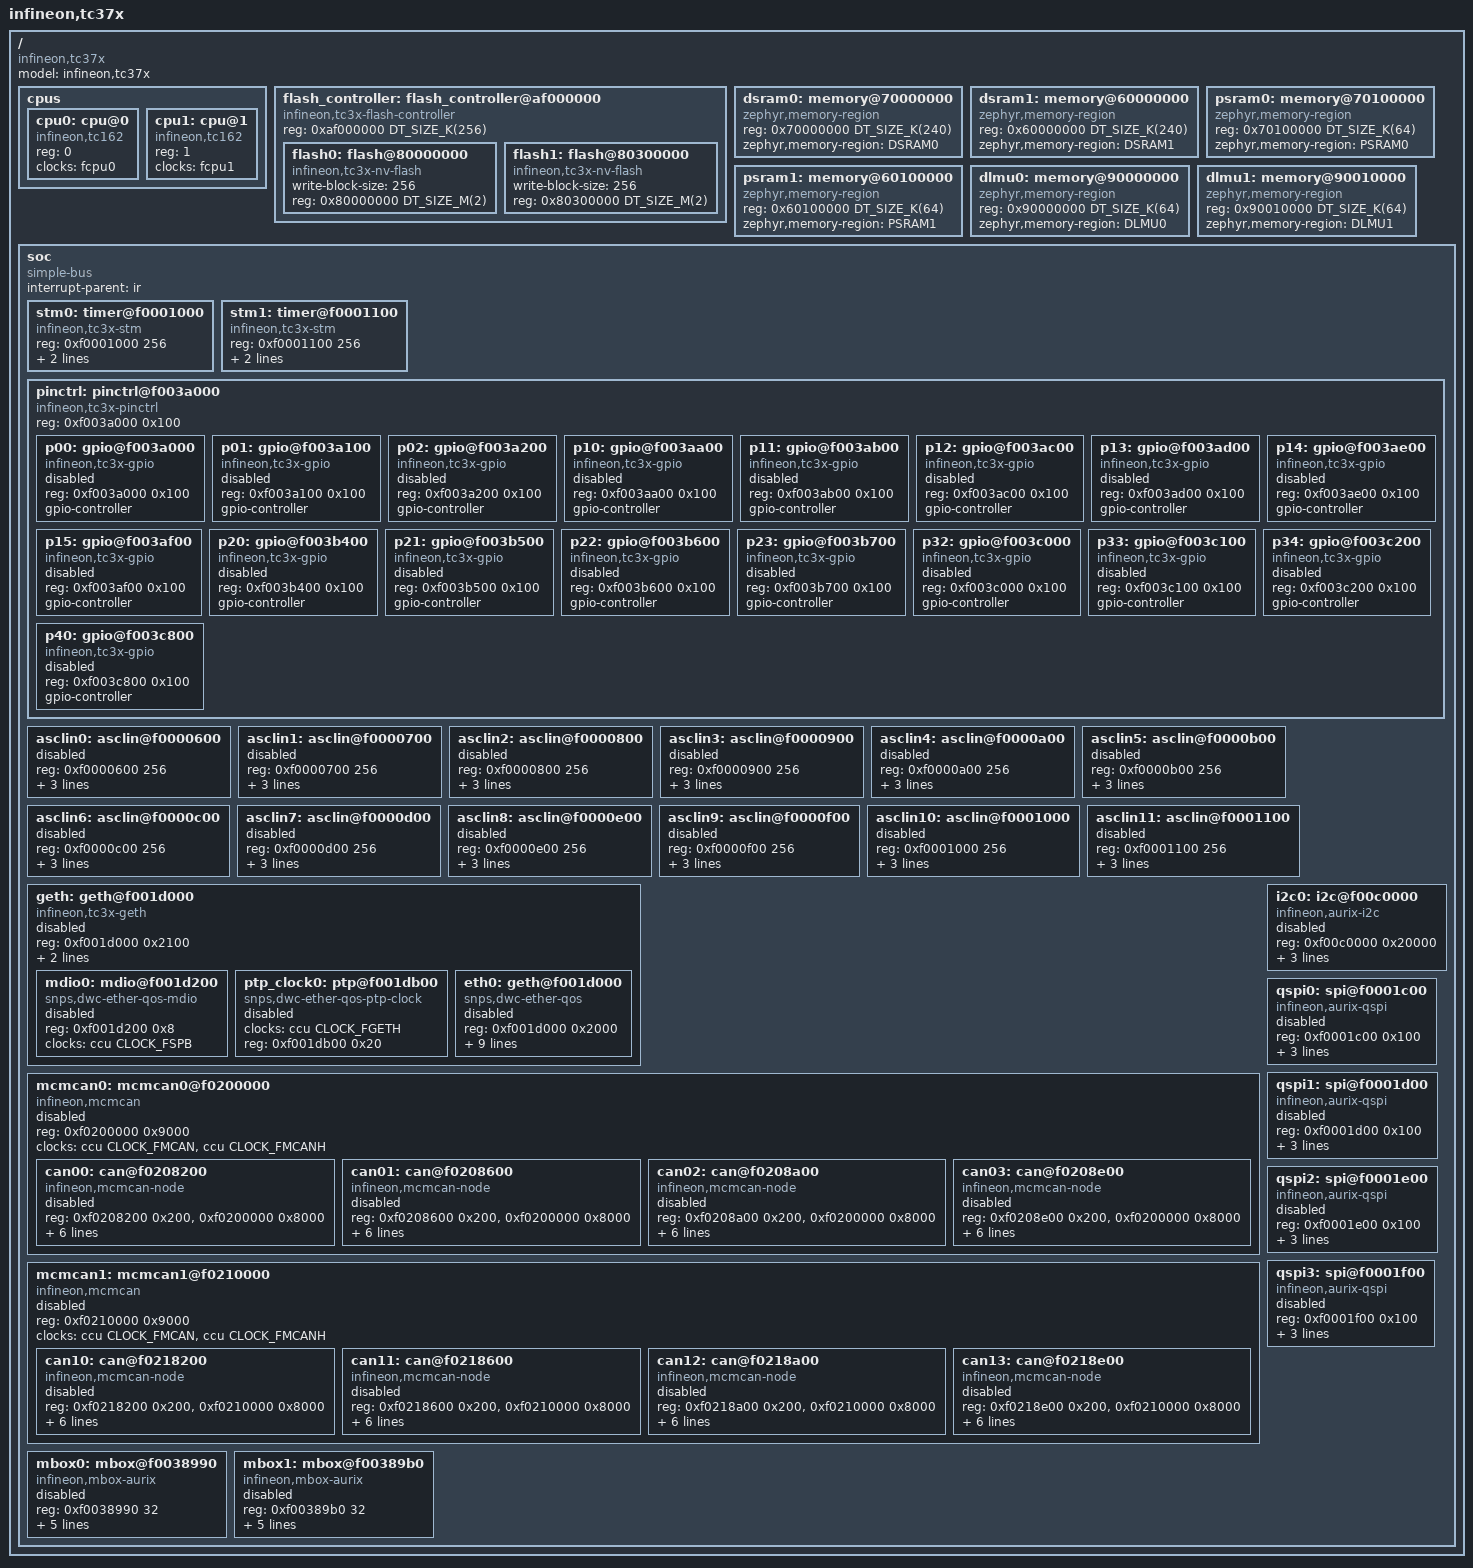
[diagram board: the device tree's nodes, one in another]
/*
 * Copyright (c) 2026 Infineon Technologies AG
 *
 * SPDX-License-Identifier: Apache-2.0
 */

#include <mem.h>
#include <freq.h>
#include <skeleton.dtsi>
#include <zephyr/dt-bindings/clock/tc3x_clock.h>
#include <zephyr/dt-bindings/gpio/gpio.h>
#include <infineon/tc3x/tc36x-irq.h>
#include <infineon/tc3x/tc3x-common.dtsi>

/ {
	model = "infineon,tc37x";
	compatible = "infineon,tc37x";

	cpus {
		#address-cells = <1>;
		#size-cells = <0>;

		cpu0: cpu@0 {
			compatible = "infineon,tc162";
			reg = <0>;
			clocks = <&fcpu0>;
		};

		cpu1: cpu@1 {
			compatible = "infineon,tc162";
			reg = <1>;
			clocks = <&fcpu1>;
		};
	};

	flash_controller: flash_controller@af000000 {
		compatible = "infineon,tc3x-flash-controller";
		#address-cells = <1>;
		#size-cells = <1>;
		reg = <0xaf000000 DT_SIZE_K(256)>;

		flash0: flash@80000000 {
			compatible = "infineon,tc3x-nv-flash", "soc-nv-flash";
			write-block-size = <256>;
			reg = <0x80000000 DT_SIZE_M(2)>;
		};

		flash1: flash@80300000 {
			compatible = "infineon,tc3x-nv-flash", "soc-nv-flash";
			write-block-size = <256>;
			reg = <0x80300000 DT_SIZE_M(2)>;
		};
	};

	dsram0: memory@70000000 {
		compatible = "zephyr,memory-region", "mmio-sram";
		reg = <0x70000000 DT_SIZE_K(240)>;
		zephyr,memory-region = "DSRAM0";
	};

	dsram1: memory@60000000 {
		compatible = "zephyr,memory-region", "mmio-sram";
		reg = <0x60000000 DT_SIZE_K(240)>;
		zephyr,memory-region = "DSRAM1";
	};

	psram0: memory@70100000 {
		compatible = "zephyr,memory-region", "mmio-sram";
		reg = <0x70100000 DT_SIZE_K(64)>;
		zephyr,memory-region = "PSRAM0";
	};

	psram1: memory@60100000 {
		compatible = "zephyr,memory-region", "mmio-sram";
		reg = <0x60100000 DT_SIZE_K(64)>;
		zephyr,memory-region = "PSRAM1";
	};

	dlmu0: memory@90000000 {
		compatible = "zephyr,memory-region", "mmio-sram";
		reg = <0x90000000 DT_SIZE_K(64)>;
		zephyr,memory-region = "DLMU0";
	};

	dlmu1: memory@90010000 {
		compatible = "zephyr,memory-region", "mmio-sram";
		reg = <0x90010000 DT_SIZE_K(64)>;
		zephyr,memory-region = "DLMU1";
	};

	soc {
		#address-cells = <1>;
		#size-cells = <1>;
		interrupt-parent = <&ir>;
		compatible = "simple-bus";
		ranges;

		stm0: timer@f0001000 {
			compatible = "infineon,tc3x-stm";
			reg = <0xf0001000 256>;
			clocks = <&fstm>;
			interrupts = <IRQ_STM0_SR0 1>;
		};

		stm1: timer@f0001100 {
			compatible = "infineon,tc3x-stm";
			reg = <0xf0001100 256>;
			clocks = <&fstm>;
			interrupts = <IRQ_STM1_SR0 1>;
		};

		pinctrl: pinctrl@f003a000 {
			compatible = "infineon,tc3x-pinctrl";
			reg = <0xf003a000 0x100>;
			#address-cells = <1>;
			#size-cells = <1>;

			p00: gpio@f003a000 {
				compatible = "infineon,tc3x-gpio";
				reg = <0xf003a000 0x100>;
				gpio-controller;
				#gpio-cells = <2>;
				status = "disabled";
			};

			p01: gpio@f003a100 {
				compatible = "infineon,tc3x-gpio";
				reg = <0xf003a100 0x100>;
				gpio-controller;
				#gpio-cells = <2>;
				status = "disabled";
			};

			p02: gpio@f003a200 {
				compatible = "infineon,tc3x-gpio";
				reg = <0xf003a200 0x100>;
				gpio-controller;
				#gpio-cells = <2>;
				status = "disabled";
			};

			p10: gpio@f003aa00 {
				compatible = "infineon,tc3x-gpio";
				reg = <0xf003aa00 0x100>;
				gpio-controller;
				#gpio-cells = <2>;
				status = "disabled";
			};

			p11: gpio@f003ab00 {
				compatible = "infineon,tc3x-gpio";
				reg = <0xf003ab00 0x100>;
				gpio-controller;
				#gpio-cells = <2>;
				status = "disabled";
			};

			p12: gpio@f003ac00 {
				compatible = "infineon,tc3x-gpio";
				reg = <0xf003ac00 0x100>;
				gpio-controller;
				#gpio-cells = <2>;
				status = "disabled";
			};

			p13: gpio@f003ad00 {
				compatible = "infineon,tc3x-gpio";
				reg = <0xf003ad00 0x100>;
				gpio-controller;
				#gpio-cells = <2>;
				status = "disabled";
			};

			p14: gpio@f003ae00 {
				compatible = "infineon,tc3x-gpio";
				reg = <0xf003ae00 0x100>;
				gpio-controller;
				#gpio-cells = <2>;
				status = "disabled";
			};

			p15: gpio@f003af00 {
				compatible = "infineon,tc3x-gpio";
				reg = <0xf003af00 0x100>;
				gpio-controller;
				#gpio-cells = <2>;
				status = "disabled";
			};

			p20: gpio@f003b400 {
				compatible = "infineon,tc3x-gpio";
				reg = <0xf003b400 0x100>;
				gpio-controller;
				#gpio-cells = <2>;
				status = "disabled";
			};

			p21: gpio@f003b500 {
				compatible = "infineon,tc3x-gpio";
				reg = <0xf003b500 0x100>;
				gpio-controller;
				#gpio-cells = <2>;
				status = "disabled";
			};

			p22: gpio@f003b600 {
				compatible = "infineon,tc3x-gpio";
				reg = <0xf003b600 0x100>;
				gpio-controller;
				#gpio-cells = <2>;
				status = "disabled";
			};

			p23: gpio@f003b700 {
				compatible = "infineon,tc3x-gpio";
				reg = <0xf003b700 0x100>;
				gpio-controller;
				#gpio-cells = <2>;
				status = "disabled";
			};

			p32: gpio@f003c000 {
				compatible = "infineon,tc3x-gpio";
				reg = <0xf003c000 0x100>;
				gpio-controller;
				#gpio-cells = <2>;
				status = "disabled";
			};

			p33: gpio@f003c100 {
				compatible = "infineon,tc3x-gpio";
				reg = <0xf003c100 0x100>;
				gpio-controller;
				#gpio-cells = <2>;
				status = "disabled";
			};

			p34: gpio@f003c200 {
				compatible = "infineon,tc3x-gpio";
				reg = <0xf003c200 0x100>;
				gpio-controller;
				#gpio-cells = <2>;
				status = "disabled";
			};

			p40: gpio@f003c800 {
				compatible = "infineon,tc3x-gpio";
				reg = <0xf003c800 0x100>;
				gpio-controller;
				#gpio-cells = <2>;
				status = "disabled";
			};
		};

		asclin0: asclin@f0000600 {
			reg = <0xf0000600 256>;
			interrupts = <IRQ_ASCLIN0_TX 2>,
				     <IRQ_ASCLIN0_RX 3>,
				     <IRQ_ASCLIN0_ERR 4>;
			interrupt-names = "tx", "rx", "err";
			clocks = <&ccu CLOCK_FASCLINF>, <&ccu CLOCK_FASCLINS>;
			clock-names = "fasclinf", "fasclins";
			status = "disabled";
		};

		asclin1: asclin@f0000700 {
			reg = <0xf0000700 256>;
			interrupts = <IRQ_ASCLIN1_TX 2>,
				     <IRQ_ASCLIN1_RX 3>,
				     <IRQ_ASCLIN1_ERR 4>;
			interrupt-names = "tx", "rx", "err";
			clocks = <&ccu CLOCK_FASCLINF>, <&ccu CLOCK_FASCLINS>;
			clock-names = "fasclinf", "fasclins";
			status = "disabled";
		};

		asclin2: asclin@f0000800 {
			reg = <0xf0000800 256>;
			interrupts = <IRQ_ASCLIN2_TX 2>,
				     <IRQ_ASCLIN2_RX 3>,
				     <IRQ_ASCLIN2_ERR 4>;
			interrupt-names = "tx", "rx", "err";
			clocks = <&ccu CLOCK_FASCLINF>, <&ccu CLOCK_FASCLINS>;
			clock-names = "fasclinf", "fasclins";
			status = "disabled";
		};

		asclin3: asclin@f0000900 {
			reg = <0xf0000900 256>;
			interrupts = <IRQ_ASCLIN3_TX 2>,
				     <IRQ_ASCLIN3_RX 3>,
				     <IRQ_ASCLIN3_ERR 4>;
			interrupt-names = "tx", "rx", "err";
			clocks = <&ccu CLOCK_FASCLINF>, <&ccu CLOCK_FASCLINS>;
			clock-names = "fasclinf", "fasclins";
			status = "disabled";
		};

		asclin4: asclin@f0000a00 {
			reg = <0xf0000a00 256>;
			interrupts = <IRQ_ASCLIN4_TX 2>,
				     <IRQ_ASCLIN4_RX 3>,
				     <IRQ_ASCLIN4_ERR 4>;
			interrupt-names = "tx", "rx", "err";
			clocks = <&ccu CLOCK_FASCLINF>, <&ccu CLOCK_FASCLINS>;
			clock-names = "fasclinf", "fasclins";
			status = "disabled";
		};

		asclin5: asclin@f0000b00 {
			reg = <0xf0000b00 256>;
			interrupts = <IRQ_ASCLIN5_TX 2>,
				     <IRQ_ASCLIN5_RX 3>,
				     <IRQ_ASCLIN5_ERR 4>;
			interrupt-names = "tx", "rx", "err";
			clocks = <&ccu CLOCK_FASCLINF>, <&ccu CLOCK_FASCLINS>;
			clock-names = "fasclinf", "fasclins";
			status = "disabled";
		};

		asclin6: asclin@f0000c00 {
			reg = <0xf0000c00 256>;
			interrupts = <IRQ_ASCLIN6_TX 2>,
				     <IRQ_ASCLIN6_RX 3>,
				     <IRQ_ASCLIN6_ERR 4>;
			interrupt-names = "tx", "rx", "err";
			clocks = <&ccu CLOCK_FASCLINF>, <&ccu CLOCK_FASCLINS>;
			clock-names = "fasclinf", "fasclins";
			status = "disabled";
		};

		asclin7: asclin@f0000d00 {
			reg = <0xf0000d00 256>;
			interrupts = <IRQ_ASCLIN7_TX 2>,
				     <IRQ_ASCLIN7_RX 3>,
				     <IRQ_ASCLIN7_ERR 4>;
			interrupt-names = "tx", "rx", "err";
			clocks = <&ccu CLOCK_FASCLINF>, <&ccu CLOCK_FASCLINS>;
			clock-names = "fasclinf", "fasclins";
			status = "disabled";
		};

		asclin8: asclin@f0000e00 {
			reg = <0xf0000e00 256>;
			interrupts = <IRQ_ASCLIN8_TX 2>,
				     <IRQ_ASCLIN8_RX 3>,
				     <IRQ_ASCLIN8_ERR 4>;
			interrupt-names = "tx", "rx", "err";
			clocks = <&ccu CLOCK_FASCLINF>, <&ccu CLOCK_FASCLINS>;
			clock-names = "fasclinf", "fasclins";
			status = "disabled";
		};

		asclin9: asclin@f0000f00 {
			reg = <0xf0000f00 256>;
			interrupts = <IRQ_ASCLIN9_TX 2>, <IRQ_ASCLIN9_RX 3>, <IRQ_ASCLIN9_ERR 4>;
			interrupt-names = "tx", "rx", "err";
			clocks = <&ccu CLOCK_FASCLINF>, <&ccu CLOCK_FASCLINS>;
			clock-names = "fasclinf", "fasclins";
			status = "disabled";
		};

		asclin10: asclin@f0001000 {
			reg = <0xf0001000 256>;
			interrupts = <IRQ_ASCLIN10_TX 2>, <IRQ_ASCLIN10_RX 3>, <IRQ_ASCLIN10_ERR 4>;
			interrupt-names = "tx", "rx", "err";
			clocks = <&ccu CLOCK_FASCLINF>, <&ccu CLOCK_FASCLINS>;
			clock-names = "fasclinf", "fasclins";
			status = "disabled";
		};

		asclin11: asclin@f0001100 {
			reg = <0xf0001100 256>;
			interrupts = <IRQ_ASCLIN11_TX 2>, <IRQ_ASCLIN11_RX 3>, <IRQ_ASCLIN11_ERR 4>;
			interrupt-names = "tx", "rx", "err";
			clocks = <&ccu CLOCK_FASCLINF>, <&ccu CLOCK_FASCLINS>;
			clock-names = "fasclinf", "fasclins";
			status = "disabled";
		};

		geth: geth@f001d000 {
			reg = <0xf001d000 0x2100>;
			compatible = "infineon,tc3x-geth";
			#address-cells = <1>;
			#size-cells = <1>;
			clocks = <&ccu CLOCK_FSPB>, <&ccu CLOCK_FGETH>, <&ccu CLOCK_FGETH>;
			clock-names = "csr", "app", "ptp";
			status = "disabled";

			mdio0: mdio@f001d200 {
				compatible = "snps,dwc-ether-qos-mdio";
				reg = <0xf001d200 0x8>;
				clocks = <&ccu CLOCK_FSPB>;
				#address-cells = <1>;
				#size-cells = <0>;
				status = "disabled";
			};

			ptp_clock0: ptp@f001db00 {
				compatible = "snps,dwc-ether-qos-ptp-clock";
				clocks = <&ccu CLOCK_FGETH>;
				reg = <0xf001db00 0x20>;
				status = "disabled";
			};

			eth0: geth@f001d000 {
				compatible = "snps,dwc-ether-qos";
				reg = <0xf001d000 0x2000>;
				interrupts = <IRQ_GETH0_SR0 10>,
					     <IRQ_GETH0_SR2 12>,
					     <IRQ_GETH0_SR3 13>,
					     <IRQ_GETH0_SR4 14>,
					     <IRQ_GETH0_SR5 15>,
					     <IRQ_GETH0_SR6 16>,
					     <IRQ_GETH0_SR7 17>,
					     <IRQ_GETH0_SR8 18>,
					     <IRQ_GETH0_SR9 19>;
				interrupt-names = "common",
						  "tx_ch0",
						  "tx_ch1",
						  "tx_ch2",
						  "tx_ch3",
						  "rx_ch0",
						  "rx_ch1",
						  "rx_ch2",
						  "rx_ch3";
				snps,ptp-clock = <&ptp_clock0>;
				snps,address-aligned-burst;
				snps,fixed-burst-length;
				snps,burst-length = <8>;
				status = "disabled";
			};
		};

		mcmcan0: mcmcan0@f0200000 {
			compatible = "infineon,mcmcan";
			#address-cells = <1>;
			#size-cells = <1>;
			reg = <0xf0200000 0x9000>;
			clocks = <&ccu CLOCK_FMCAN>, <&ccu CLOCK_FMCANH>;
			status = "disabled";

			can00: can@f0208200 {
				compatible = "infineon,mcmcan-node";
				reg = <0xf0208200 0x200>, <0xf0200000 0x8000>;
				reg-names = "m_can", "message_ram";
				interrupts = <IRQ_CAN0_INT0 10>, <IRQ_CAN0_INT1 11>;
				interrupt-names = "line0", "line1";
				bosch,mram-cfg = <0x0 32 32 32 32 0 16 16>;
				sample-point = <875>;
				sample-point-data = <875>;
				bitrate = <500000>;
				bitrate-data = <2000000>;
				status = "disabled";
			};

			can01: can@f0208600 {
				compatible = "infineon,mcmcan-node";
				reg = <0xf0208600 0x200>, <0xf0200000 0x8000>;
				reg-names = "m_can", "message_ram";
				interrupts = <IRQ_CAN0_INT2 10>, <IRQ_CAN0_INT3 11>;
				interrupt-names = "line0", "line1";
				bosch,mram-cfg = <0x0 32 32 32 32 0 16 16>;
				sample-point = <875>;
				sample-point-data = <875>;
				bitrate = <500000>;
				bitrate-data = <2000000>;
				status = "disabled";
			};

			can02: can@f0208a00 {
				compatible = "infineon,mcmcan-node";
				reg = <0xf0208a00 0x200>, <0xf0200000 0x8000>;
				reg-names = "m_can", "message_ram";
				interrupts = <IRQ_CAN0_INT4 10>, <IRQ_CAN0_INT5 11>;
				interrupt-names = "line0", "line1";
				bosch,mram-cfg = <0x0 32 32 32 32 0 16 16>;
				sample-point = <875>;
				sample-point-data = <875>;
				bitrate = <500000>;
				bitrate-data = <2000000>;
				status = "disabled";
			};

			can03: can@f0208e00 {
				compatible = "infineon,mcmcan-node";
				reg = <0xf0208e00 0x200>, <0xf0200000 0x8000>;
				reg-names = "m_can", "message_ram";
				interrupts = <IRQ_CAN0_INT6 10>, <IRQ_CAN0_INT7 11>;
				interrupt-names = "line0", "line1";
				bosch,mram-cfg = <0x0 32 32 32 32 0 16 16>;
				sample-point = <875>;
				sample-point-data = <875>;
				bitrate = <500000>;
				bitrate-data = <2000000>;
				status = "disabled";
			};
		};

		mcmcan1: mcmcan1@f0210000 {
			compatible = "infineon,mcmcan";
			#address-cells = <1>;
			#size-cells = <1>;
			reg = <0xf0210000 0x9000>;
			clocks = <&ccu CLOCK_FMCAN>, <&ccu CLOCK_FMCANH>;
			status = "disabled";

			can10: can@f0218200 {
				compatible = "infineon,mcmcan-node";
				reg = <0xf0218200 0x200>, <0xf0210000 0x8000>;
				reg-names = "m_can", "message_ram";
				interrupts = <IRQ_CAN1_INT0 10>, <IRQ_CAN1_INT1 11>;
				interrupt-names = "line0", "line1";
				bosch,mram-cfg = <0x0 32 32 32 32 0 16 16>;
				sample-point = <875>;
				sample-point-data = <875>;
				bitrate = <500000>;
				bitrate-data = <2000000>;
				status = "disabled";
			};

			can11: can@f0218600 {
				compatible = "infineon,mcmcan-node";
				reg = <0xf0218600 0x200>, <0xf0210000 0x8000>;
				reg-names = "m_can", "message_ram";
				interrupts = <IRQ_CAN1_INT2 10>, <IRQ_CAN1_INT3 11>;
				interrupt-names = "line0", "line1";
				bosch,mram-cfg = <0x0 32 32 32 32 0 16 16>;
				sample-point = <875>;
				sample-point-data = <875>;
				bitrate = <500000>;
				bitrate-data = <2000000>;
				status = "disabled";
			};

			can12: can@f0218a00 {
				compatible = "infineon,mcmcan-node";
				reg = <0xf0218a00 0x200>, <0xf0210000 0x8000>;
				reg-names = "m_can", "message_ram";
				interrupts = <IRQ_CAN1_INT4 10>, <IRQ_CAN1_INT5 11>;
				interrupt-names = "line0", "line1";
				bosch,mram-cfg = <0x0 32 32 32 32 0 16 16>;
				sample-point = <875>;
				sample-point-data = <875>;
				bitrate = <500000>;
				bitrate-data = <2000000>;
				status = "disabled";
			};

			can13: can@f0218e00 {
				compatible = "infineon,mcmcan-node";
				reg = <0xf0218e00 0x200>, <0xf0210000 0x8000>;
				reg-names = "m_can", "message_ram";
				interrupts = <IRQ_CAN1_INT6 10>, <IRQ_CAN1_INT7 11>;
				interrupt-names = "line0", "line1";
				bosch,mram-cfg = <0x0 32 32 32 32 0 16 16>;
				sample-point = <875>;
				sample-point-data = <875>;
				bitrate = <500000>;
				bitrate-data = <2000000>;
				status = "disabled";
			};
		};

		i2c0: i2c@f00c0000 {
			compatible = "infineon,aurix-i2c";
			reg = <0xf00c0000 0x20000>;
			#address-cells = <1>;
			#size-cells = <0>;
			clocks = <&ccu CLOCK_FI2C>;
			interrupts = <IRQ_I2C0_DTR 5>, <IRQ_I2C0_ERR 6>, <IRQ_I2C0_P 5>;
			interrupt-names = "data_transfer", "error", "protocol";
			status = "disabled";
		};

		qspi0: spi@f0001c00 {
			compatible = "infineon,aurix-qspi";
			reg = <0xf0001c00 0x100>;
			#address-cells = <1>;
			#size-cells = <0>;
			interrupts = <IRQ_QSPI0_TX 0x2>,
				     <IRQ_QSPI0_RX 0x3>,
				     <IRQ_QSPI0_ERR 0x3>;
			interrupt-names = "tx", "rx", "err";
			clocks = <&ccu CLOCK_FQSPI>;
			status = "disabled";
		};

		qspi1: spi@f0001d00 {
			compatible = "infineon,aurix-qspi";
			reg = <0xf0001d00 0x100>;
			#address-cells = <1>;
			#size-cells = <0>;
			interrupts = <IRQ_QSPI1_TX 0x2>,
				     <IRQ_QSPI1_RX 0x3>,
				     <IRQ_QSPI1_ERR 0x3>;
			interrupt-names = "tx", "rx", "err";
			clocks = <&ccu CLOCK_FQSPI>;
			status = "disabled";
		};

		qspi2: spi@f0001e00 {
			compatible = "infineon,aurix-qspi";
			reg = <0xf0001e00 0x100>;
			#address-cells = <1>;
			#size-cells = <0>;
			interrupts = <IRQ_QSPI2_TX 0x2>,
				     <IRQ_QSPI2_RX 0x3>,
				     <IRQ_QSPI2_ERR 0x3>;
			interrupt-names = "tx", "rx", "err";
			clocks = <&ccu CLOCK_FQSPI>;
			status = "disabled";
		};

		qspi3: spi@f0001f00 {
			compatible = "infineon,aurix-qspi";
			reg = <0xf0001f00 0x100>;
			#address-cells = <1>;
			#size-cells = <0>;
			interrupts = <IRQ_QSPI3_TX 0x2>,
				     <IRQ_QSPI3_RX 0x3>,
				     <IRQ_QSPI3_ERR 0x3>;
			interrupt-names = "tx", "rx", "err";
			clocks = <&ccu CLOCK_FQSPI>;
			status = "disabled";
		};

		mbox0: mbox@f0038990 {
			compatible = "infineon,mbox-aurix";
			reg = <0xf0038990 32>;
			interrupts = <IRQ_GPSR0_SR0 10>,
				     <IRQ_GPSR0_SR1 10>,
				     <IRQ_GPSR0_SR2 10>,
				     <IRQ_GPSR0_SR3 10>,
				     <IRQ_GPSR0_SR4 10>,
				     <IRQ_GPSR0_SR5 10>,
				     <IRQ_GPSR0_SR6 10>,
				     <IRQ_GPSR0_SR7 10>;
			#mbox-cells = <1>;
			status = "disabled";
		};

		mbox1: mbox@f00389b0 {
			compatible = "infineon,mbox-aurix";
			reg = <0xf00389b0 32>;
			interrupts = <IRQ_GPSR1_SR0 10>,
				     <IRQ_GPSR1_SR1 10>,
				     <IRQ_GPSR1_SR2 10>,
				     <IRQ_GPSR1_SR3 10>,
				     <IRQ_GPSR1_SR4 10>,
				     <IRQ_GPSR1_SR5 10>,
				     <IRQ_GPSR1_SR6 10>,
				     <IRQ_GPSR1_SR7 10>;
			#mbox-cells = <1>;
			status = "disabled";
		};
	};
};
